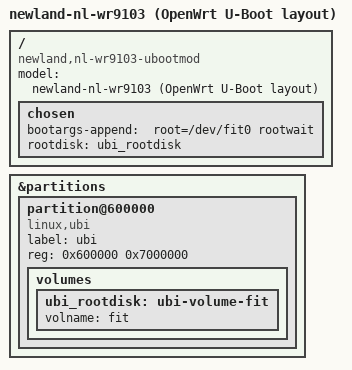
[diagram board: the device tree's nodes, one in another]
@@ -0,0 +1,28 @@
// SPDX-License-Identifier: GPL-2.0-or-later OR MIT

/dts-v1/;
#include "mt7981-newland-nl-wr9103.dtsi"

/ {
	model = "newland-nl-wr9103 (OpenWrt U-Boot layout)";
	compatible = "newland,nl-wr9103-ubootmod", "mediatek,mt7981";

	chosen {
		bootargs-append = " root=/dev/fit0 rootwait";
		rootdisk = <&ubi_rootdisk>;
	};
};

&partitions {
	partition@600000 {
		label = "ubi";
		reg = <0x600000 0x7000000>;
				compatible = "linux,ubi";

				volumes {
					ubi_rootdisk: ubi-volume-fit {More actions
						volname = "fit";
					};
				};
	};
};
